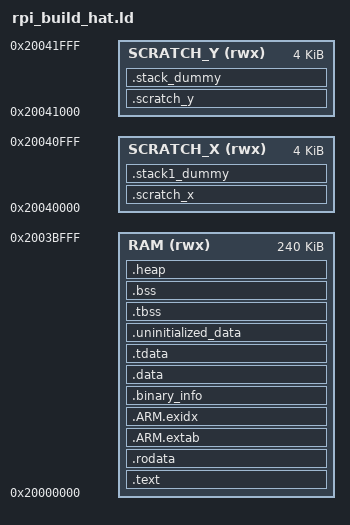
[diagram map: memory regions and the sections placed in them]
/*
Modified from
pico-sdk/src/rp2_common/pico_standard_link/memmap_no_flash.ld
to limit RAM use to 240K for use with bootloader.
*/
/* Based on GCC ARM embedded samples.
   Defines the following symbols for use by code:
    __exidx_start
    __exidx_end
    __etext
    __data_start__
    __preinit_array_start
    __preinit_array_end
    __init_array_start
    __init_array_end
    __fini_array_start
    __fini_array_end
    __data_end__
    __bss_start__
    __bss_end__
    __end__
    end
    __HeapLimit
    __StackLimit
    __StackTop
    __stack (== StackTop)
*/

MEMORY
{
    RAM(rwx) : ORIGIN =  0x20000000, LENGTH = 240k      /* <--- changed here */
    SCRATCH_X(rwx) : ORIGIN = 0x20040000, LENGTH = 4k
    SCRATCH_Y(rwx) : ORIGIN = 0x20041000, LENGTH = 4k
}

ENTRY(_entry_point)

SECTIONS
{
    /* Note in NO_FLASH builds the entry point for both the bootrom, and debugger
       entry (ELF entry point), are *first* in the image, and the vector table
       follows immediately afterward. This is because the bootrom enters RAM
       binaries directly at their lowest address (preferring main RAM over XIP
       cache-as-SRAM if both are used).
    */

    .text : {
        __logical_binary_start = .;
        __reset_start = .;
        KEEP (*(.reset))
        __reset_end = .;
        KEEP (*(.binary_info_header))
        __binary_info_header_end = .;
        KEEP (*(.embedded_block))
        __embedded_block_end = .;
        . = ALIGN(256);
        KEEP (*(.vectors))
        *(.time_critical*)
        *(.text*)
        . = ALIGN(4);
        *(.init)
        *(.fini)
        /* Pull all c'tors into .text */
        *crtbegin.o(.ctors)
        *crtbegin?.o(.ctors)
        *(EXCLUDE_FILE(*crtend?.o *crtend.o) .ctors)
        *(SORT(.ctors.*))
        *(.ctors)
        /* Followed by destructors */
        *crtbegin.o(.dtors)
        *crtbegin?.o(.dtors)
        *(EXCLUDE_FILE(*crtend?.o *crtend.o) .dtors)
        *(SORT(.dtors.*))
        *(.dtors)

        *(.eh_frame*)
    } > RAM

    .rodata : {
        . = ALIGN(4);
        *(.rodata*)
        . = ALIGN(4);
        *(SORT_BY_ALIGNMENT(SORT_BY_NAME(.flashdata*)))
        . = ALIGN(4);
    } > RAM

    .ARM.extab :
    {
        *(.ARM.extab* .gnu.linkonce.armextab.*)
    } > RAM

    __exidx_start = .;
    .ARM.exidx :
    {
        *(.ARM.exidx* .gnu.linkonce.armexidx.*)
    } > RAM
    __exidx_end = .;

    /* Machine inspectable binary information */
    . = ALIGN(4);
    __binary_info_start = .;
    .binary_info :
    {
        KEEP(*(.binary_info.keep.*))
        *(.binary_info.*)
    } > RAM
    __binary_info_end = .;
    . = ALIGN(4);

    .data : {
        __data_start__ = .;
        *(vtable)
        *(.data*)

        . = ALIGN(4);
        *(.after_data.*)
        . = ALIGN(4);
        /* preinit data */
        PROVIDE_HIDDEN (__mutex_array_start = .);
        KEEP(*(SORT(.mutex_array.*)))
        KEEP(*(.mutex_array))
        PROVIDE_HIDDEN (__mutex_array_end = .);

        . = ALIGN(4);
        /* preinit data */
        PROVIDE_HIDDEN (__preinit_array_start = .);
        KEEP(*(SORT(.preinit_array.*)))
        KEEP(*(.preinit_array))
        PROVIDE_HIDDEN (__preinit_array_end = .);

        . = ALIGN(4);
        /* init data */
        PROVIDE_HIDDEN (__init_array_start = .);
        KEEP(*(SORT(.init_array.*)))
        KEEP(*(.init_array))
        PROVIDE_HIDDEN (__init_array_end = .);

        . = ALIGN(4);
        /* finit data */
        PROVIDE_HIDDEN (__fini_array_start = .);
        *(SORT(.fini_array.*))
        *(.fini_array)
        PROVIDE_HIDDEN (__fini_array_end = .);

        *(.jcr)
        . = ALIGN(4);
   } > RAM

    .tdata : {
        . = ALIGN(4);
		*(.tdata .tdata.* .gnu.linkonce.td.*)
        /* All data end */
        __tdata_end = .;
    } > RAM
    PROVIDE(__data_end__ = .);

    .uninitialized_data (NOLOAD): {
        . = ALIGN(4);
        *(.uninitialized_data*)
    } > RAM
    /* __etext is (for backwards compatibility) the name of the .data init source pointer (...) */
    __etext = LOADADDR(.data);

    .tbss (NOLOAD) : {
        . = ALIGN(4);
        __bss_start__ = .;
        __tls_base = .;
        *(.tbss .tbss.* .gnu.linkonce.tb.*)
        *(.tcommon)

        __tls_end = .;
    } > RAM

    .bss (NOLOAD) : {
        . = ALIGN(4);
        __tbss_end = .;

        *(SORT_BY_ALIGNMENT(SORT_BY_NAME(.bss*)))
        *(COMMON)
        . = ALIGN(4);
        __bss_end__ = .;
    } > RAM

    .heap (NOLOAD):
    {
        __end__ = .;
        end = __end__;
        KEEP(*(.heap*))
        __HeapLimit = .;
    } > RAM

    /* Start and end symbols must be word-aligned */
    .scratch_x : {
        __scratch_x_start__ = .;
        *(.scratch_x.*)
        . = ALIGN(4);
        __scratch_x_end__ = .;
    } > SCRATCH_X
    __scratch_x_source__ = LOADADDR(.scratch_x);

    .scratch_y : {
        __scratch_y_start__ = .;
        *(.scratch_y.*)
        . = ALIGN(4);
        __scratch_y_end__ = .;
    } > SCRATCH_Y
    __scratch_y_source__ = LOADADDR(.scratch_y);

    /* .stack*_dummy section doesn't contains any symbols. It is only
     * used for linker to calculate size of stack sections, and assign
     * values to stack symbols later
     *
     * stack1 section may be empty/missing if platform_launch_core1 is not used */

    /* by default we put core 0 stack at the end of scratch Y, so that if core 1
     * stack is not used then all of SCRATCH_X is free.
     */
    .stack1_dummy (NOLOAD):
    {
        /* This depends on PICO_STACK_SIZE. Right now, it is set to 8KiB, so
         * we are using both SCRATCH_X and SCRATCH_Y for core 0 stack and
         * not using core 1. */
        pbdrv_stack_start = .;
        *(.stack1*)
    } > SCRATCH_X
    .stack_dummy (NOLOAD):
    {
        KEEP(*(.stack*))
        pbdrv_stack_end = .;
    } > SCRATCH_Y

    /* stack limit is poorly named, but historically is maximum heap ptr */
    __StackLimit = __bss_end__;

    /* Define start and end of GC heap */
    pbsys_storage_heap_start = __StackLimit; /* after the C heap (sbrk limit) */
    pbsys_storage_heap_end = ORIGIN(RAM) + LENGTH(RAM);

    /* Define memory for the C stack */
    __StackOneTop = ORIGIN(SCRATCH_X) + LENGTH(SCRATCH_X);
    __StackTop = ORIGIN(SCRATCH_Y) + LENGTH(SCRATCH_Y);
    __StackOneBottom = __StackOneTop - SIZEOF(.stack1_dummy);
    __StackBottom = __StackTop - SIZEOF(.stack_dummy);
    PROVIDE(__stack = __StackTop);

    /* Check GC heap is at least 32 KB */
    /* This is quarter the minimum RAM suggested for full-featured MicroPython.
     * This value accounts for large static buffers included in user C or C++
     * modules, which might significantly reduce the available heap but also
     * lower demand for memory at runtime.
     */
    ASSERT((pbsys_storage_heap_end - pbsys_storage_heap_start) > 32*1024, "GcHeap is too small")

    ASSERT( __binary_info_header_end - __logical_binary_start <= 256, "Binary info must be in first 256 bytes of the binary")
    /* todo assert on extra code */
}
